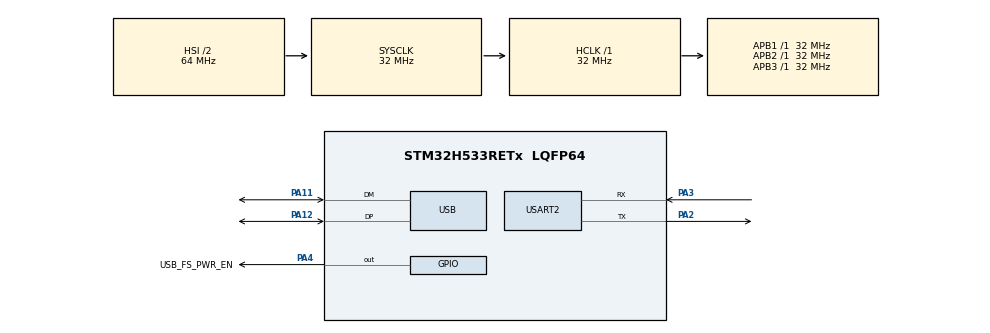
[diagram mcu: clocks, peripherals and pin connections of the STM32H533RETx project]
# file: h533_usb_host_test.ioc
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BOOTPATH.BootPathName=LEGACY
BOOTPATH.UserSelectedBootPath=LEGACY
CORTEX_M33_NS.userName=CORTEX_M33
FILEX.useRTOS=1
Mcu.Family=STM32H5
Mcu.Name=STM32H533RETx
Mcu.Package=LQFP64
NVIC.PriorityGroup=NVIC_PRIORITYGROUP_4
NVIC.TIM1_UP_IRQn=true\:15\:0\:false\:false\:true\:false\:false\:true\:true
NVIC.TimeBase=TIM1_UP_IRQn
NVIC.TimeBaseIP=TIM1
NVIC.USB_DRD_FS_IRQn=true\:0\:0\:false\:false\:true\:false\:true\:true\:true
PA11.Mode=Host
PA11.Signal=USB_DM
PA12.Mode=Host
PA12.Signal=USB_DP
PA2.Mode=Asynchronous
PA2.Signal=USART2_TX
PA3.Mode=Asynchronous
PA3.Signal=USART2_RX
PA4.GPIO_Label=USB_FS_PWR_EN
PA4.Signal=GPIO_Output
ProjectManager.HeapSize=0x200
ProjectManager.StackSize=0x400
ProjectManager.TargetToolchain=STM32CubeIDE
RCC.ADCFreq_Value=32000000
RCC.AHBFreq_Value=32000000
RCC.APB1Freq_Value=32000000
RCC.APB1TimFreq_Value=32000000
RCC.APB2Freq_Value=32000000
RCC.APB2TimFreq_Value=32000000
RCC.APB3Freq_Value=32000000
RCC.CSI_VALUE=4000000
RCC.CortexFreq_Value=32000000
RCC.EPOD_VALUE=4000000
RCC.HCLKFreq_Value=32000000
RCC.HSE_VALUE=25000000
RCC.HSI48_VALUE=48000000
RCC.HSI_VALUE=64000000
RCC.LSE_VALUE=32768
RCC.LSIRC_VALUE=32000
RCC.SYSCLKFreq_VALUE=32000000
RCC.USBFreq_Value=48000000
RCC.VCOOutputFreq_Value=516000000
USART2.VirtualMode-Asynchronous=VM_ASYNC
USB.VirtualMode=Host_Only
USBX.BSP.number=2
USBX.Core_System=1
USBX.USBX_HOST_SYS_SIZE=0x8000
USBX.UX_HOST_APP_MEM_POOL_SIZE=0xA000
USBX.UX_Host_Controller=1
USBX.UX_Host_CoreStack=1
USBX.UX_Host_class_HUB=1
USBX0.BSP.STBoard=false
USBX0.BSP.api=Unknown
USBX0.BSP.condition=\!USBPD_USB_SUPPORT
USBX0.BSP.instance=PA4
USBX0.BSP.ip=GPIO
USBX0.BSP.mode=Output
USBX0.BSP.name=Drive_VBUS_FS
USBX0.BSP.solution=PA4
USBX1.BSP.STBoard=false
USBX1.BSP.api=Unknown
USBX1.BSP.instance=USB
USBX1.BSP.ip=USB
USBX1.BSP.mode=Host_Only
USBX1.BSP.name=USB_Host
USBX1.BSP.solution=USB
VP_BOOTPATH_VS_BOOTPATH.Mode=BP_Activate
VP_CORTEX_M33_NS_VS_Hclk.Mode=Hclk_Mode
VP_FILEX_VS_FileOoSystemJjFileXJjCore.Mode=FileX_Core
VP_ICACHE_VS_ICACHE.Mode=DirectMappedCache
VP_MEMORYMAP_VS_MEMORYMAP.Mode=CurAppReg
VP_PWR_VS_LPOM.Mode=PowerOptimisation
VP_PWR_VS_SECSignals.Mode=Security/Privilege
VP_SYS_VS_tim1.Mode=TIM1
VP_THREADX_VS_RTOSJjThreadXJjCoreJjDefault.Mode=Core_Default
VP_USBX_Core_System.Mode=Core_System
VP_USBX_UX\ Host\ Controller_FS.Mode=UX_Host_Controller_FS
VP_USBX_UX\ Host\ CoreStack_FS.Mode=UX_Host_CoreStack_FS
VP_USBX_UX\ Host\ HUB_FS.Mode=UX_Host_class_HUB_FS
board=custom

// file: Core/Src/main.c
/* USER CODE BEGIN Header */
/**
  ******************************************************************************
  * @file           : main.c
  * @brief          : Main program body
  ******************************************************************************
  * @attention
  *
  * Copyright (c) 2026 STMicroelectronics.
  * All rights reserved.
  *
  * This software is licensed under terms that can be found in the LICENSE file
  * in the root directory of this software component.
  * If no LICENSE file comes with this software, it is provided AS-IS.
  *
  ******************************************************************************
  */
/* USER CODE END Header */
#include "app_threadx.h"
#include "main.h"

/* USER CODE BEGIN Includes */
#include <stdio.h>

/* USER CODE END Includes */

UART_HandleTypeDef huart2;

HCD_HandleTypeDef hhcd_USB_DRD_FS;

void SystemClock_Config(void);
static void MX_GPIO_Init(void);
static void MX_USART2_UART_Init(void);
static void MX_ICACHE_Init(void);
static void MX_USB_HCD_Init(void);

int main(void)
{

  /* MCU Configuration--------------------------------------------------------*/

  /* Reset of all peripherals, Initializes the Flash interface and the Systick. */
  HAL_Init();

  /* Configure the system clock */
  SystemClock_Config();

  /* Initialize all configured peripherals */
  MX_GPIO_Init();
  MX_USART2_UART_Init();
  MX_ICACHE_Init();
  MX_USB_HCD_Init();
  /* USER CODE BEGIN 2 */
  printf("Hello, USB host\r\n");

  /* USER CODE END 2 */

  MX_ThreadX_Init();

  /* We should never get here as control is now taken by the scheduler */

  /* Infinite loop */
  while (1)
  {

  }
}

void SystemClock_Config(void)
{
  RCC_OscInitTypeDef RCC_OscInitStruct = {0};
  RCC_ClkInitTypeDef RCC_ClkInitStruct = {0};

  /** Configure the main internal regulator output voltage
  */
  __HAL_PWR_VOLTAGESCALING_CONFIG(PWR_REGULATOR_VOLTAGE_SCALE3);

  while(!__HAL_PWR_GET_FLAG(PWR_FLAG_VOSRDY)) {}

  /** Initializes the RCC Oscillators according to the specified parameters
  * in the RCC_OscInitTypeDef structure.
  */
  RCC_OscInitStruct.OscillatorType = RCC_OSCILLATORTYPE_HSI48|RCC_OSCILLATORTYPE_HSI;
  RCC_OscInitStruct.HSIState = RCC_HSI_ON;
  RCC_OscInitStruct.HSIDiv = RCC_HSI_DIV2;
  RCC_OscInitStruct.HSICalibrationValue = RCC_HSICALIBRATION_DEFAULT;
  RCC_OscInitStruct.HSI48State = RCC_HSI48_ON;
  RCC_OscInitStruct.PLL.PLLState = RCC_PLL_NONE;
  if (HAL_RCC_OscConfig(&RCC_OscInitStruct) != HAL_OK)
  {
    Error_Handler();
  }

  /** Initializes the CPU, AHB and APB buses clocks
  */
  RCC_ClkInitStruct.ClockType = RCC_CLOCKTYPE_HCLK|RCC_CLOCKTYPE_SYSCLK
                              |RCC_CLOCKTYPE_PCLK1|RCC_CLOCKTYPE_PCLK2
                              |RCC_CLOCKTYPE_PCLK3;
  RCC_ClkInitStruct.SYSCLKSource = RCC_SYSCLKSOURCE_HSI;
  RCC_ClkInitStruct.AHBCLKDivider = RCC_SYSCLK_DIV1;
  RCC_ClkInitStruct.APB1CLKDivider = RCC_HCLK_DIV1;
  RCC_ClkInitStruct.APB2CLKDivider = RCC_HCLK_DIV1;
  RCC_ClkInitStruct.APB3CLKDivider = RCC_HCLK_DIV1;

  if (HAL_RCC_ClockConfig(&RCC_ClkInitStruct, FLASH_LATENCY_1) != HAL_OK)
  {
    Error_Handler();
  }

  /** Configure the programming delay
  */
  __HAL_FLASH_SET_PROGRAM_DELAY(FLASH_PROGRAMMING_DELAY_0);
}

static void MX_ICACHE_Init(void)
{

  /** Enable instruction cache in 1-way (direct mapped cache)
  */
  if (HAL_ICACHE_ConfigAssociativityMode(ICACHE_1WAY) != HAL_OK)
  {
    Error_Handler();
  }
  if (HAL_ICACHE_Enable() != HAL_OK)
  {
    Error_Handler();
  }

}

static void MX_USART2_UART_Init(void)
{

  huart2.Instance = USART2;
  huart2.Init.BaudRate = 115200;
  huart2.Init.WordLength = UART_WORDLENGTH_8B;
  huart2.Init.StopBits = UART_STOPBITS_1;
  huart2.Init.Parity = UART_PARITY_NONE;
  huart2.Init.Mode = UART_MODE_TX_RX;
  huart2.Init.HwFlowCtl = UART_HWCONTROL_NONE;
  huart2.Init.OverSampling = UART_OVERSAMPLING_16;
  huart2.Init.OneBitSampling = UART_ONE_BIT_SAMPLE_DISABLE;
  huart2.Init.ClockPrescaler = UART_PRESCALER_DIV1;
  huart2.AdvancedInit.AdvFeatureInit = UART_ADVFEATURE_NO_INIT;
  if (HAL_UART_Init(&huart2) != HAL_OK)
  {
    Error_Handler();
  }
  if (HAL_UARTEx_SetTxFifoThreshold(&huart2, UART_TXFIFO_THRESHOLD_1_8) != HAL_OK)
  {
    Error_Handler();
  }
  if (HAL_UARTEx_SetRxFifoThreshold(&huart2, UART_RXFIFO_THRESHOLD_1_8) != HAL_OK)
  {
    Error_Handler();
  }
  if (HAL_UARTEx_DisableFifoMode(&huart2) != HAL_OK)
  {
    Error_Handler();
  }

}

static void MX_USB_HCD_Init(void)
{

  hhcd_USB_DRD_FS.Instance = USB_DRD_FS;
  hhcd_USB_DRD_FS.Init.dev_endpoints = 8;
  hhcd_USB_DRD_FS.Init.Host_channels = 8;
  hhcd_USB_DRD_FS.Init.speed = USBD_FS_SPEED;
  hhcd_USB_DRD_FS.Init.phy_itface = HCD_PHY_EMBEDDED;
  hhcd_USB_DRD_FS.Init.Sof_enable = DISABLE;
  hhcd_USB_DRD_FS.Init.low_power_enable = DISABLE;
  hhcd_USB_DRD_FS.Init.vbus_sensing_enable = DISABLE;
  hhcd_USB_DRD_FS.Init.bulk_doublebuffer_enable = DISABLE;
  hhcd_USB_DRD_FS.Init.iso_singlebuffer_enable = DISABLE;
  if (HAL_HCD_Init(&hhcd_USB_DRD_FS) != HAL_OK)
  {
    Error_Handler();
  }

}

static void MX_GPIO_Init(void)
{
  GPIO_InitTypeDef GPIO_InitStruct = {0};

  /* GPIO Ports Clock Enable */
  __HAL_RCC_GPIOA_CLK_ENABLE();

  /*Configure GPIO pin Output Level */
  HAL_GPIO_WritePin(USB_FS_PWR_EN_GPIO_Port, USB_FS_PWR_EN_Pin, GPIO_PIN_RESET);

  /*Configure GPIO pin : USB_FS_PWR_EN_Pin */
  GPIO_InitStruct.Pin = USB_FS_PWR_EN_Pin;
  GPIO_InitStruct.Mode = GPIO_MODE_OUTPUT_PP;
  GPIO_InitStruct.Pull = GPIO_NOPULL;
  GPIO_InitStruct.Speed = GPIO_SPEED_FREQ_LOW;
  HAL_GPIO_Init(USB_FS_PWR_EN_GPIO_Port, &GPIO_InitStruct);

}

/* USER CODE BEGIN 4 */
int _write(int file, char *ptr, int len)
{
    (void)file;
    HAL_UART_Transmit(&huart2, (uint8_t*)ptr, (uint16_t)len, HAL_MAX_DELAY);
    return len;
}

/* USER CODE END 4 */

void HAL_TIM_PeriodElapsedCallback(TIM_HandleTypeDef *htim)
{
  if (htim->Instance == TIM1)
  {
    HAL_IncTick();
  }
}

void Error_Handler(void)
{
  __disable_irq();
  while (1)
  {
  }
}
